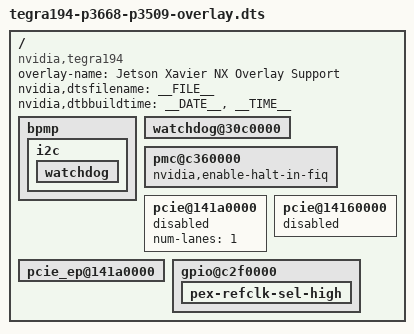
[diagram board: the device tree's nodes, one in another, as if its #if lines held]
/*
 * Copyright (c) 2019-2022, NVIDIA CORPORATION.  All rights reserved.
 *
 * This program is free software; you can redistribute it and/or modify
 * it under the terms of the GNU General Public License as published by
 * the Free Software Foundation; either version 2 of the License, or
 * (at your option) any later version.
 *
 * This program is distributed in the hope that it will be useful, but WITHOUT
 * ANY WARRANTY; without even the implied warranty of MERCHANTABILITY or
 * FITNESS FOR A PARTICULAR PURPOSE.  See the GNU General Public License for
 * more details.
 *
 */

/*
 * Device-tree overlay for tegra194-overlay-p3668-p3509.dts for T194 platform.
 */

/dts-v1/;

/ {
	overlay-name = "Jetson Xavier NX Overlay Support";
	compatible = "nvidia,tegra194";
	nvidia,dtsfilename = __FILE__;
	nvidia,dtbbuildtime = __DATE__, __TIME__;

	fragment@0 {
		target-path = "/";
		board_config {
			odm-data = "enable-pmic-wdt";
		};
		__overlay__ {
#if TEGRA_BPMP_FW_DT_VERSION >= DT_VERSION_2
			bpmp { i2c {
#else
			bpmp_i2c {
#endif
				watchdog {
					status = "okay";
				};
#if TEGRA_BPMP_FW_DT_VERSION >= DT_VERSION_2
			}; };
#else
			};
#endif
		};
	};

	fragment@1 {
		target-path = "/";
		board_config {
			odm-data = "enable-denver-wdt";
		};
		__overlay__ {
			watchdog@30c0000 {
				status = "okay";
			};
		};
	};

	fragment@2 {
		target-path = "/";
		board_config {
			odm-data = "disable-denver-wdt";
		};
		__overlay__ {
			pmc@c360000 {
				nvidia,enable-halt-in-fiq;
			};
		};
	};

	/* pcie-c5-c4-num-lanes */
	fragment@3 {
		target-path = "/";
		board_config {
			ids = ">=3449-0000-000";
		};
		__overlay__ {
			pcie@141a0000 {
				num-lanes = <1>;
				status = "okay";
			};
			pcie_ep@141a0000 {
				status = "disabled";
			};
			pcie@14160000 {
				status = "disabled";
			};
		};
	};

	/* pcie-c5-ep */
	fragment@5 {
		target-path = "/";
		board_config {
			odm-data = "pcie-c5-endpoint-enable", "NVHS_PCIE";
		};
		__overlay__ {
			pcie@141a0000 {
				status = "disabled";
			};
			pcie_ep@141a0000 {
				status = "okay";
			};
#if TEGRA_PCIE_VERSION < DT_VERSION_2
			gpio@c2f0000 {
				pex-refclk-sel-high {
					status = "okay";
				};
			};
#endif
		};
	};
};
